# MK20D5 register map
File version: 1.6
Registers are 8-bit, read-write, reset 0x0 unless marked. A register's access mark holds for its fields unless they carry their own. Offsets are from the block's base; [hi:lo] are bit positions; {n}, {i} and the like mark numbered series.

## USBDCD — USB Device Charger Detection module
Base 0x40035000; register names take the prefix USBDCD_
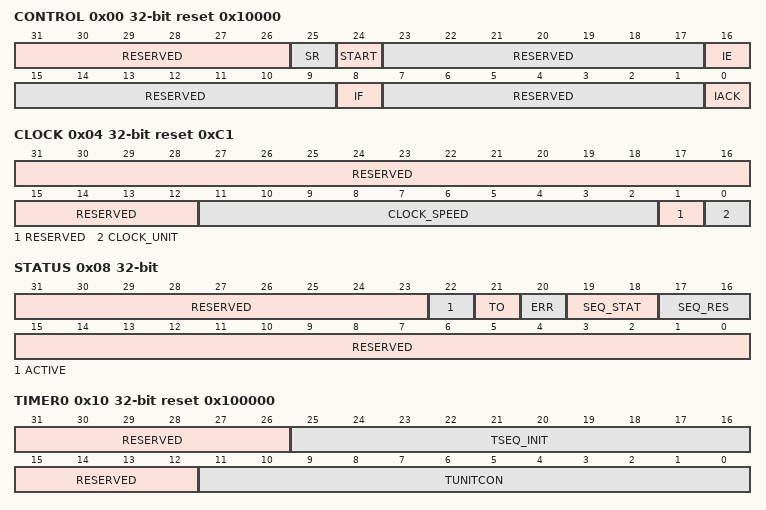
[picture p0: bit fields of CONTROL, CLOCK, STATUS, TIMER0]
0x00 CONTROL 32-bit access per field reset 0x10000
  [31:26] RESERVED ro
  [25] SR wo — Software Reset
    0=Do not perform a software reset; 1=Perform a software reset
  [24] START wo — Start Change Detection Sequence
    0=Do not start the sequence. Writes of this value have no effect.; 1=Initiate the charger detection sequence. If the sequence is already running, writes of this value have no effect.
  [23:17] RESERVED ro
  [16] IE rw — Interrupt Enable
    0=Disable interrupts to the system; 1=Enable interrupts to the system
  [15:9] RESERVED rw
  [8] IF ro — Interrupt Flag
    0=No interrupt is pending; 1=An interrupt is pending
  [7:1] RESERVED ro
  [0] IACK wo — Interrupt Acknowledge
    0=Do not clear the interrupt; 1=Clear the IF bit (interrupt flag)
0x04 CLOCK 32-bit access per field reset 0xC1
  [31:12] RESERVED ro
  [11:2] CLOCK_SPEED rw — Numerical Value of Clock Speed in Binary
  [1] RESERVED ro
  [0] CLOCK_UNIT rw — Unit of measurement encoding for Clock Speed
    0=kHz Speed (between 1 kHz and 1023 kHz); 1=MHz Speed (between 1 MHz and 1023 MHz)
0x08 STATUS 32-bit ro
  [31:23] RESERVED
  [22] ACTIVE — Active Status Indicator
    0=The sequence is not running; 1=The sequence is running
  [21] TO — Timeout Flag
    0=The detection sequence has not been running for over 1 s; 1=It has been over 1 s since the data pin contact was detected and debounced.{
  [20] ERR — Error Flag
    0=No sequence errors; 1=Error in the detection sequence. See the SEQ_STAT field to determine the phase in which the error occurred.
  [19:18] SEQ_STAT — Charger Detection Sequence Status
    0=The module is either not enabled, or the module is enabled but the data pins have not yet been detected; 1=Data pin contact detection is complete; 2=Charger detection is complete; 3=Charger type detection is complete
  [17:16] SEQ_RES — Charger Detection Sequence Results
    0=No results to report; 1=Attached to a standard host. Must comply with USB Spec 2.0 by drawing only 2.5mA (max) until connected.; 2=Attached to a charging port. The exact meaning depends on bit 18: 0: Attached to either a charging host or a dedicated charger (The charger type detection has not completed.) 1: Attached to a charging host (The charger type detection has completed.); 3=Attached to a dedicated charger
  [15:0] RESERVED
0x10 TIMER0 32-bit access per field reset 0x100000
  [31:26] RESERVED ro
  [25:16] TSEQ_INIT rw — Sequence Initiation Time
  [15:12] RESERVED ro
  [11:0] TUNITCON ro — Unit Connection Timer Elapse (in ms)
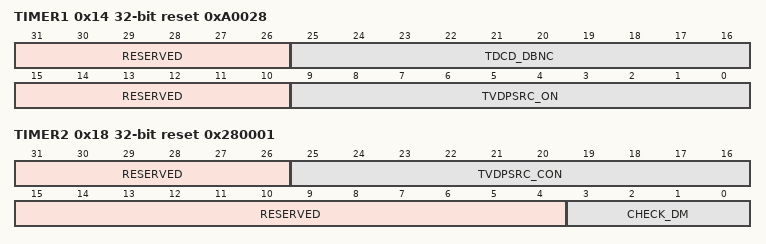
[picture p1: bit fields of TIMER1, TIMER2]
0x14 TIMER1 32-bit access per field reset 0xA0028
  [31:26] RESERVED ro
  [25:16] TDCD_DBNC rw — Time Period to Debounce D+ Signal
  [15:10] RESERVED ro
  [9:0] TVDPSRC_ON rw — Time Period Comparator Enabled
0x18 TIMER2 32-bit access per field reset 0x280001
  [31:26] RESERVED ro
  [25:16] TVDPSRC_CON rw — Time Period Before Enabling D+ Pullup
  [15:4] RESERVED ro
  [3:0] CHECK_DM rw — Time Before Check of D- Line

## PIT — Periodic Interrupt Timer
Base 0x40037000; register names take the prefix PIT_
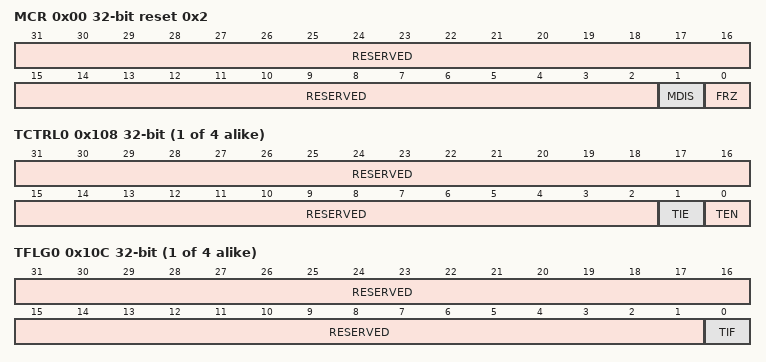
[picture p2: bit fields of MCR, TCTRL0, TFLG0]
0x00 MCR 32-bit access per field reset 0x2 — PIT Module Control Register
  [31:2] RESERVED ro
  [1] MDIS rw — Module Disable
    0=Clock for PIT Timers is enabled; 1=Clock for PIT Timers is disabled
  [0] FRZ rw — Freeze
    0=Timers continue to run in debug mode; 1=Timers are stopped in debug mode
{0x100+0x10*i} LDVAL{i} (i=0..3) 32-bit — Timer Load Value Register
  [31:0] TSV — Timer Start Value Bits
{0x104+0x10*i} CVAL{i} (i=0..3) 32-bit ro — Current Timer Value Register
  [31:0] TVL — Current Timer Value
{0x108+0x10*i} TCTRL{i} (i=0..3) 32-bit access per field — Timer Control Register
  [31:2] RESERVED ro
  [1] TIE rw — Timer Interrupt Enable Bit.
    0=Interrupt requests from Timer n are disabled; 1=Interrupt will be requested whenever TIF is set
  [0] TEN rw — Timer Enable Bit.
    0=Timer n is disabled; 1=Timer n is active
{0x10C+0x10*i} TFLG{i} (i=0..3) 32-bit access per field — Timer Flag Register
  [31:1] RESERVED ro
  [0] TIF rw — Timer Interrupt Flag.
    0=Time-out has not yet occurred; 1=Time-out has occurred
